# PIC16F1527 register map
Vendor: Microchip
Registers are 8-bit, read-write, no defined reset value unless marked. A register's access mark holds for its fields unless they carry their own. Addresses are absolute, and some are shared; only a register's first bit layout is shown; [hi:lo] are bit positions; {n}, {i} and the like mark numbered series; 'fields as' and 'values as' point back to an identical list.

## SFR
0x00 INDF0 — (power-on value xxxxxxxx)
0x01 INDF1 — (power-on value xxxxxxxx)
0x02 PCL reset 0x0
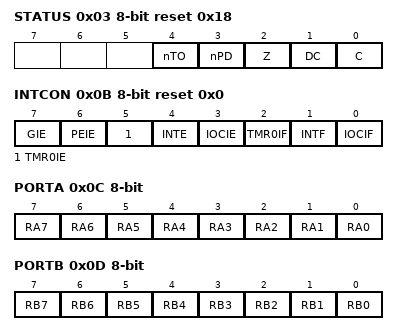
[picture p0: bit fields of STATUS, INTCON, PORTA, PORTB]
0x03 STATUS reset 0x18
  [4] nTO ro, [3] nPD ro, [2] Z, [1] DC, [0] C
0x04 FSR0L reset 0x0
0x05 FSR0H reset 0x0
0x06 FSR1L reset 0x0
0x07 FSR1H reset 0x0
0x08 BSR reset 0x0
  [4:0] BSR
0x09 WREG reset 0x0
  [7:0] WREG0
0x0A PCLATH reset 0x0
  [6:0] PCLATH
0x0B INTCON reset 0x0
  [7] GIE, [6] PEIE, [5] TMR0IE, [4] INTE, [3] IOCIE, [2] TMR0IF, [1] INTF, [0] IOCIF ro
0x0C PORTA — (power-on value xxxxxxxx)
  [n] RA{n} (n=0..7)
0x0D PORTB — (power-on value xxxxxxxx)
  [n] RB{n} (n=0..7)
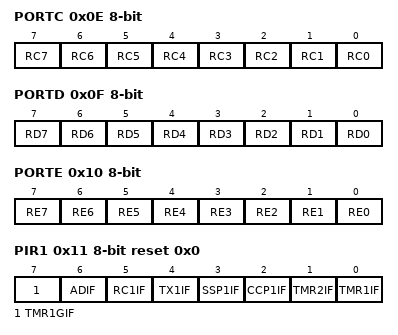
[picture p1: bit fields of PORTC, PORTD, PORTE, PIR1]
0x0E PORTC — (power-on value xxxxxxxx)
  [n] RC{n} (n=0..7)
0x0F PORTD — (power-on value xxxxxxxx)
  [n] RD{n} (n=0..7)
0x10 PORTE — (power-on value xxxxxxxx)
  [n] RE{n} (n=4..7), [3] RE3 ro, [2] RE2, [1] RE1, [0] RE0
0x11 PIR1 reset 0x0
  [7] TMR1GIF — Timer1 Gate Interrupt Flag bit
  [6] ADIF — A/D Converter Interrupt Flag bit
  [5] RC1IF ro — EUSART Receive Interrupt Flag bit
  [4] TX1IF ro — EUSART Transmit Interrupt Flag bit
  [3] SSP1IF — Master Synchronous Serial Port (MSSP) Interrupt Flag bit
  [2] CCP1IF — CCP1 Interrupt Flag bit
  [1] TMR2IF — TMR2 to PR2 Match Interrupt Flag bit
  [0] TMR1IF — TMR1 Overflow Interrupt Flag bit
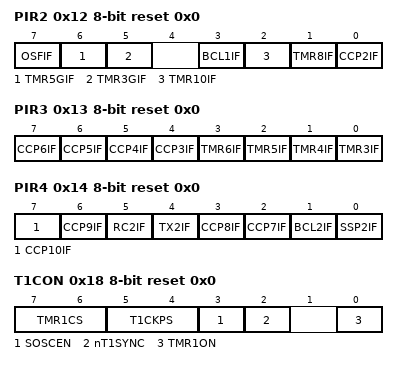
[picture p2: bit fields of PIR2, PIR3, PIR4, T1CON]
0x12 PIR2 reset 0x0
  [7] OSFIF, [6] TMR5GIF, [5] TMR3GIF, [3] BCL1IF, [2] TMR10IF, [1] TMR8IF, [0] CCP2IF
0x13 PIR3 reset 0x0
  [n+1] CCP{n}IF (n=3..6), [n-3] TMR{n}IF (n=3..6)
0x14 PIR4 reset 0x0
  [7] CCP10IF, [6] CCP9IF, [5] RC2IF, [4] TX2IF, [3] CCP8IF, [2] CCP7IF, [1] BCL2IF, [0] SSP2IF
0x15 TMR0 — (power-on value xxxxxxxx)
0x16 TMR1L — (power-on value xxxxxxxx)
0x17 TMR1H — (power-on value xxxxxxxx)
0x18 T1CON reset 0x0
  [7:6] TMR1CS, [5:4] T1CKPS, [3] SOSCEN, [2] nT1SYNC, [0] TMR1ON
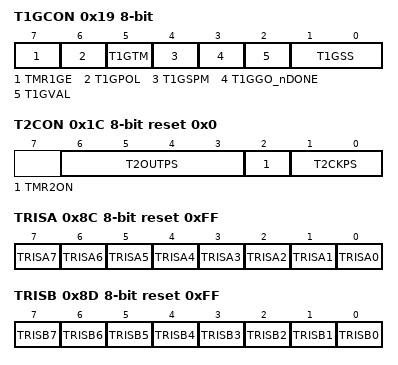
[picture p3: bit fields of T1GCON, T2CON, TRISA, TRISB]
0x19 T1GCON — (power-on value 00000x00)
  [7] TMR1GE, [6] T1GPOL, [5] T1GTM, [4] T1GSPM, [3] T1GGO_nDONE, [2] T1GVAL ro, [1:0] T1GSS
0x1A TMR2 reset 0x0
0x1B PR2 reset 0xFF
0x1C T2CON reset 0x0
  [6:3] T2OUTPS, [2] TMR2ON, [1:0] T2CKPS
0x8C TRISA reset 0xFF — PORTA Data Direction Control Register
  [n] TRISA{n} (n=0..7)
0x8D TRISB reset 0xFF — PORTB Data Direction Control Register
  [n] TRISB{n} (n=0..7)
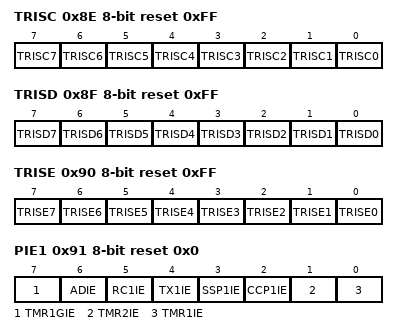
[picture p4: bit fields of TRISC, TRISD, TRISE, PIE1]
0x8E TRISC reset 0xFF — PORTC Data Direction Control Register
  [n] TRISC{n} (n=0..7)
0x8F TRISD reset 0xFF — PORTD Data Direction Control Register
  [n] TRISD{n} (n=0..7)
0x90 TRISE reset 0xFF — PORTE Data Direction Control Register
  [n] TRISE{n} (n=0..7)
0x91 PIE1 reset 0x0 — Peripheral Interrupt Enable Register 1
  [7] TMR1GIE — Timer1 Gate Interrupt Enable bit
  [6] ADIE — A/D Converter Interrupt Enable bit
  [5] RC1IE — EUSART Receive Interrupt Enable bit
  [4] TX1IE — EUSART Transmit Interrupt Enable bit
  [3] SSP1IE — Master Synchronous Serial Port (MSSP) Interrupt Enable bit
  [2] CCP1IE — CCP1 Interrupt Enable bit
  [1] TMR2IE — TMR2 to PR2 Match Interrupt Enable bit
  [0] TMR1IE — TMR1 Overflow Interrupt Enable bit
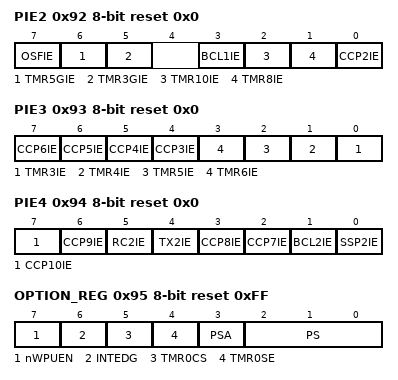
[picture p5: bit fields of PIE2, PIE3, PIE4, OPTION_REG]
0x92 PIE2 reset 0x0 — Peripheral Interrupt Enable Register 2
  [7] OSFIE — CCP2 Interrupt Enable bit
  [6] TMR5GIE
  [5] TMR3GIE
  [3] BCL1IE — MSSP Bus Collision Interrupt Interrupt Enable bit
  [2] TMR10IE
  [1] TMR8IE
  [0] CCP2IE — CCP2 Interrupt Enable bit
0x93 PIE3 reset 0x0 — Peripheral Interrupt Enable Register 3
  [n+1] CCP{n}IE (n=3..6), [n-3] TMR{n}IE (n=3..6)
0x94 PIE4 reset 0x0 — Peripheral Interrupt Enable Register 4
  [7] CCP10IE, [6] CCP9IE, [5] RC2IE, [4] TX2IE, [3] CCP8IE, [2] CCP7IE, [1] BCL2IE, [0] SSP2IE
0x95 OPTION_REG reset 0xFF — Option Register
  [7] nWPUEN — Weak Pull-up Enable bit
  [6] INTEDG — Interrupt Edge Select bit
  [5] TMR0CS — TMR0 Clock Source Select bit
  [4] TMR0SE — TMR0 Source Edge Select bit
  [3] PSA — Prescaler Active bit
  [2:0] PS
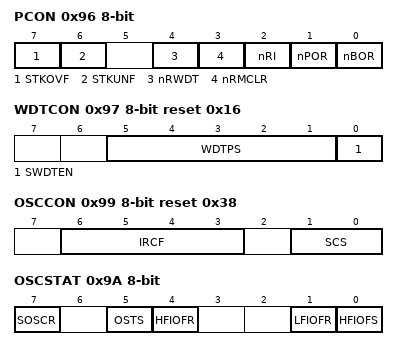
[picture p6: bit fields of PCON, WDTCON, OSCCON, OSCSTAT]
0x96 PCON — Power Control Register (power-on value 00-111qq)
  [7] STKOVF — Stack Overflow Flag bit
  [6] STKUNF — Stack Underflow Flag bit
  [4] nRWDT
  [3] nRMCLR — MCLR Reset Flag bit
  [2] nRI — RESET Instruction Flag bit
  [1] nPOR — Power-on Reset Status bit
  [0] nBOR — Brown-out Reset Status bit
0x97 WDTCON reset 0x16 — Watchdog Timer Control Register
  [5:1] WDTPS — Watchdog Timer Period Select bits
  [0] SWDTEN — Software Enable/Disable for Watch Dog Timer bit
0x99 OSCCON reset 0x38 — Oscillator Control Register
  [6:3] IRCF — Internal Oscillator Frequency Select bits
  [1:0] SCS — System clock select bit
0x9A OSCSTAT ro — Oscillator Status Register (power-on value 0-q0--00)
  [7] SOSCR — Secondary Oscillator Ready bit
  [5] OSTS — Oscillator Start-up Time-out Status bit
  [4] HFIOFR
  [1] LFIOFR — Low Freqency Internal Oscillator Ready bit
  [0] HFIOFS — Low Freqency Internal Oscillator Ready bit
0x9B ADRESL — A/D Result Register LSB (power-on value xxxxxxxx)
0x9C ADRESH — A/D Result Register MSB (power-on value xxxxxxxx)
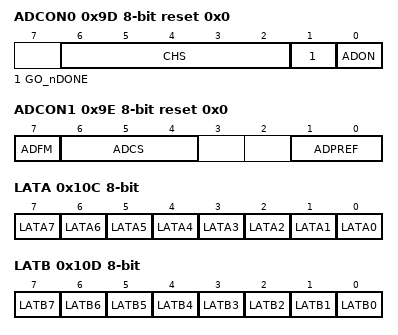
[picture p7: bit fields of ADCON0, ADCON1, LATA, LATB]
0x9D ADCON0 reset 0x0 — Analog-to-Digital Control Register 0
  [6:2] CHS — Analog Channel Select bits
  [1] GO_nDONE — A/D Conversion Status bit
  [0] ADON — A/D Module Enable bit
0x9E ADCON1 reset 0x0 — Analog-to-Digital Control Register 1
  [7] ADFM — A/D Result Format Select bit
  [6:4] ADCS — A/D Conversion Clock Select bits
  [1:0] ADPREF — A/D Positive Voltage Reference Configuration
0x10C LATA — (power-on value xxxxxxxx)
  [n] LATA{n} (n=0..7)
0x10D LATB — (power-on value xxxxxxxx)
  [n] LATB{n} (n=0..7)
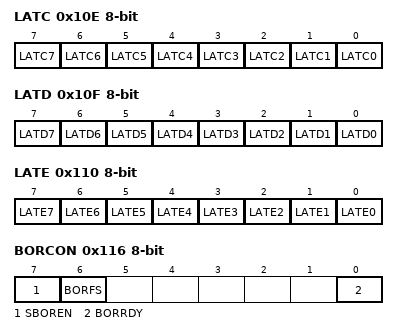
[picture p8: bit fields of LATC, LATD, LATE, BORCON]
0x10E LATC — (power-on value xxxxxxxx)
  [n] LATC{n} (n=0..7)
0x10F LATD — (power-on value xxxxxxxx)
  [n] LATD{n} (n=0..7)
0x110 LATE — (power-on value xxxxxxxx)
  [n] LATE{n} (n=0..7)
0x116 BORCON — Brown-out Reset Control Register (power-on value 10-----q)
  [7] SBOREN — Software Brown Out Reset Enable bit
  [6] BORFS
  [0] BORRDY ro — Brown-out Reset Circuit Ready Status bit
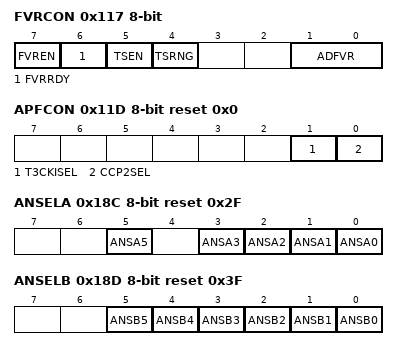
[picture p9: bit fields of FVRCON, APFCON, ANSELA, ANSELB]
0x117 FVRCON — Voltage Reference Control Register 0 (power-on value 0q00--00)
  [7] FVREN — Fixed Voltage Reference Enable
  [6] FVRRDY ro — Fixed Voltage Reference Ready Flag
  [5] TSEN — Temperature Sensor Enable
  [4] TSRNG — Temperature Sensor Range Select
  [1:0] ADFVR — A/D Converter Fixed Voltage Reference Selection
0x11D APFCON reset 0x0 — Alternate Pin Function Control Register
  [1] T3CKISEL
  [0] CCP2SEL — CCP2 Input/Output Pin Selection
0x18C ANSELA reset 0x2F
  [5] ANSA5, [n] ANSA{n} (n=0..3)
0x18D ANSELB reset 0x3F
  [n] ANSB{n} (n=0..5)
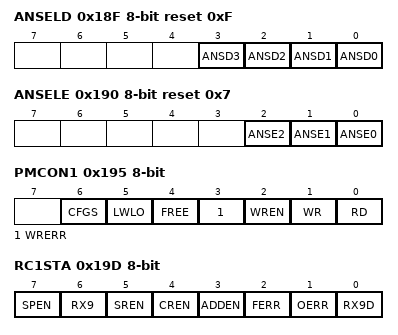
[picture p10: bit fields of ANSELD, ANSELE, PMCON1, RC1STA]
0x18F ANSELD reset 0xF
  [n] ANSD{n} (n=0..3)
0x190 ANSELE reset 0x7
  [2] ANSE2, [1] ANSE1, [0] ANSE0
0x191 PMADRL reset 0x0
0x192 PMADRH reset 0x80
  [6:0] PMADRH
0x193 PMDATL — (power-on value xxxxxxxx)
0x194 PMDATH — (power-on value --xxxxxx)
  [5:0] PMDATH
0x195 PMCON1 — (power-on value 1000x000)
  [6] CFGS — FLASH Program / Configuration Select bit
  [5] LWLO — Load Write Latches Only bit
  [4] FREE — Program FLASH Erase Enable bit
  [3] WRERR — Sequence Error Flag bit
  [2] WREN — Program/Erase Enable bit
  [1] WR — Write Control bit (can only be set)
  [0] RD — Read Control bit (can only be set)
0x196 PMCON2 wo
0x197 VREGCON reset 0x1
  [1] VREGPM
0x199 RC1REG ro reset 0x0
0x19A TX1REG reset 0x0
0x19B SP1BRGL reset 0x0
0x19C SP1BRGH reset 0x0
0x19D RC1STA — Receive Status and Control Register (power-on value 0000000x)
  [7] SPEN — Serial Port Enable bit
  [6] RX9 — 9-bit Receive Enable bit
  [5] SREN — Single Receive Enable bit
  [4] CREN — Continuous Receive Enable bit
  [3] ADDEN — Address Detect Enable bit
  [2] FERR ro — Framing Error bit
  [1] OERR ro — Overrun Error bit
  [0] RX9D ro — 9th bit of received data (can be parity bit)
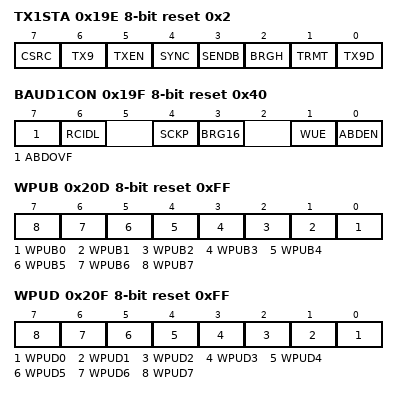
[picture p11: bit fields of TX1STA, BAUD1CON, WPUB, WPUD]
0x19E TX1STA reset 0x2 — Transmit Status and Control Register
  [7] CSRC — Clock Source Select bit
  [6] TX9 — 9-bit Transmit Enable bit
  [5] TXEN — Transmit Enable bit
  [4] SYNC — USART Mode Select bit
  [3] SENDB — Send BREAK character bit
  [2] BRGH — High Baud Rate Select bit
  [1] TRMT ro — Transmit Operation Idle Status bit
  [0] TX9D — 9th bit of transmit data; can be used as parity bit
0x19F BAUD1CON reset 0x40 — Baud Rate Control Register
  [7] ABDOVF — BRG Rollover Status bit
  [6] RCIDL ro — Receive Operation Idle Status bit
  [4] SCKP — Clock/Transmit Polarity Select bit
  [3] BRG16 — 16-bit Baud Rate Register enable bit
  [1] WUE — Wake-Up Enable bit
  [0] ABDEN — Auto-Baud Detect Enable bit
0x20D WPUB reset 0xFF
  [n] WPUB{n} (n=0..7)
0x20F WPUD reset 0xFF
  [n] WPUD{n} (n=0..7)
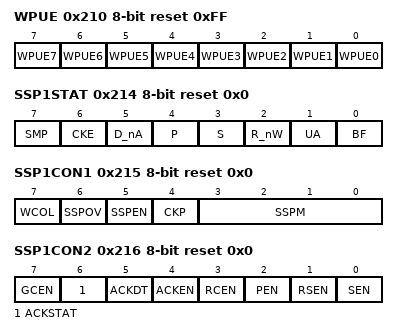
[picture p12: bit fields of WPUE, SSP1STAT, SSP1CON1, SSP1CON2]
0x210 WPUE reset 0xFF
  [n] WPUE{n} (n=0..7)
0x211 SSP1BUF — (power-on value xxxxxxxx)
  [7:0] SSPBUF
0x212 SSP1ADD reset 0x0
  [7:0] SSPADD
0x213 SSP1MSK reset 0xFF
  [7:0] SSPMSK
0x214 SSP1STAT reset 0x0
  [7] SMP, [6] CKE, [5] D_nA ro, [4] P ro, [3] S ro, [2] R_nW ro, [1] UA ro, [0] BF ro
0x215 SSP1CON1 reset 0x0
  [7] WCOL, [6] SSPOV, [5] SSPEN, [4] CKP, [3:0] SSPM
0x216 SSP1CON2 reset 0x0
  [7] GCEN, [6] ACKSTAT ro, [5] ACKDT, [4] ACKEN, [3] RCEN, [2] PEN, [1] RSEN, [0] SEN
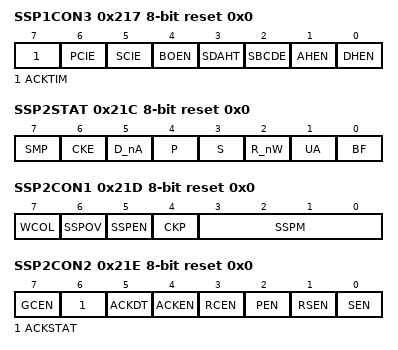
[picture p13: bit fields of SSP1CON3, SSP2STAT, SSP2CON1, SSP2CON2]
0x217 SSP1CON3 reset 0x0
  [7] ACKTIM ro, [6] PCIE, [5] SCIE, [4] BOEN, [3] SDAHT, [2] SBCDE, [1] AHEN, [0] DHEN
0x219 SSP2BUF — (power-on value xxxxxxxx)
  [7:0] SSPBUF
0x21A SSP2ADD reset 0x0
  [7:0] SSPADD
0x21B SSP2MSK reset 0xFF
  [7:0] SSPMSK
0x21C SSP2STAT reset 0x0
  fields as SSP1STAT
0x21D SSP2CON1 reset 0x0
  [7] WCOL, [6] SSPOV, [5] SSPEN, [4] CKP, [3:0] SSPM
0x21E SSP2CON2 reset 0x0
  fields as SSP1CON2
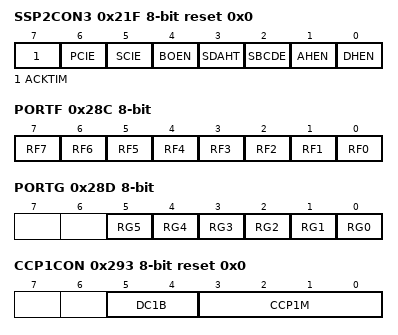
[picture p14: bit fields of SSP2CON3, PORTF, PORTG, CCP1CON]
0x21F SSP2CON3 reset 0x0
  fields as SSP1CON3
0x28C PORTF — (power-on value xxxxxxxx)
  [n] RF{n} (n=0..7)
0x28D PORTG — (power-on value --xxxxxx)
  [n] RG{n} (n=0..5)
0x291 CCPR1L — (power-on value xxxxxxxx)
0x292 CCPR1H — (power-on value xxxxxxxx)
0x293 CCP1CON reset 0x0
  [5:4] DC1B, [3:0] CCP1M
0x298 CCPR2L — (power-on value xxxxxxxx)
0x299 CCPR2H — (power-on value xxxxxxxx)
0x29A CCP2CON reset 0x0
  [5:4] DC2B, [3:0] CCP2M
0x29D CCPTMRS0 — (power-on value xxxxxxxx)
  [2n-1:2n-2] C{n}TSEL (n=1..4)
0x29E CCPTMRS1 — (power-on value xxxxxxxx)
  [2n-9:2n-10] C{n}TSEL (n=5..8)
0x29F CCPTMRS2 — (power-on value ----xxxx)
  [3:2] C10TSEL, [1:0] C9TSEL
0x30C TRISF reset 0xFF
  [n] TRISF{n} (n=0..7)
0x30D TRISG reset 0x3F
  [n] TRISG{n} (n=0..4)
0x311 CCPR3L — (power-on value xxxxxxxx)
0x312 CCPR3H — (power-on value xxxxxxxx)
0x313 CCP3CON reset 0x0
  [5:4] DC3B, [3:0] CCP3M
0x318 CCPR4L — (power-on value xxxxxxxx)
0x319 CCPR4H — (power-on value xxxxxxxx)
0x31A CCP4CON reset 0x0
  [5:4] DC4B, [3:0] CCP4M
0x31C CCPR5L — (power-on value xxxxxxxx)
0x31D CCPR5H — (power-on value xxxxxxxx)
0x31E CCP5CON reset 0x0
  [5:4] DC5B, [3:0] CCP5M
0x38C LATF — (power-on value xxxxxxxx)
  [n] LATF{n} (n=0..7)
0x38D LATG — (power-on value ---xxxxx)
  [n] LATG{n} (n=0..4)
0x394 IOCBP reset 0x0 — Interrupt-On-Change Positive Edge Register
  [n] IOCBP{n} (n=0..7)
0x395 IOCBN reset 0x0 — Interrupt-On-Change Negative Edge Register
  [n] IOCBN{n} (n=0..7)
0x396 IOCBF reset 0x0 — Interrupt-On-Change Flag Register
  [n] IOCBF{n} (n=0..7)
0x40C ANSELF reset 0xFF
  [n] ANSF{n} (n=0..7)
0x40D ANSELG reset 0x1E
  [n] ANSG{n} (n=1..4)
0x411 TMR3L — (power-on value xxxxxxxx)
0x412 TMR3H — (power-on value xxxxxxxx)
0x413 T3CON reset 0x0
  [7:6] TMR3CS, [5:4] T3CKPS, [3] SOSCEN, [2] nT3SYNC, [0] TMR3ON
0x414 T3GCON — (power-on value 00000x00)
  [7] TMR3GE, [6] T3GPOL, [5] T3GTM, [4] T3GSPM, [3] T3GGO_nDONE, [2] T3GVAL ro, [1:0] T3GSS
0x415 TMR4 reset 0x0
0x416 PR4 reset 0xFF
0x417 T4CON reset 0x0
  [6:3] T4OUTPS, [2] TMR4ON, [1:0] T4CKPS
0x418 TMR5L — (power-on value xxxxxxxx)
0x419 TMR5H — (power-on value xxxxxxxx)
0x41A T5CON reset 0x0
  [7:6] TMR5CS, [5:4] T5CKPS, [3] SOSCEN, [2] nT5SYNC, [0] TMR5ON
0x41B T5GCON — (power-on value 00000x00)
  [7] TMR5GE, [6] T5GPOL, [5] T5GTM, [4] T5GSPM, [3] T5GGO_nDONE, [2] T5GVAL ro, [1:0] T5GSS
0x41C TMR6 reset 0x0
0x41D PR6 reset 0xFF
0x41E T6CON reset 0x0
  [6:3] T6OUTPS, [2] TMR6ON, [1:0] T6CKPS
0x48D WPUG reset 0x20
  [5] WPUG5
0x491 RC2REG ro reset 0x0
0x492 TX2REG reset 0x0
0x493 SP2BRGL reset 0x0
0x494 SP2BRGH reset 0x0
0x495 RC2STA — Receive Status and Control Register (power-on value 0000000x)
  fields as RC1STA
0x496 TX2STA reset 0x2 — Transmit Status and Control Register
  fields as TX1STA
0x497 BAUD2CON reset 0x40 — Baud Rate Control Register
  fields as BAUD1CON
0x595 TMR8 reset 0x0
0x596 PR8 reset 0xFF
0x597 T8CON reset 0x0
  [6:3] T8OUTPS, [2] TMR8ON, [1:0] T8CKPS
0x59C TMR10 reset 0x0
0x59D PR10 reset 0xFF
0x59E T10CON reset 0x0
  [6:3] T10OUTPS, [2] TMR10ON, [1:0] T10CKPS
{0x5FF+3i} CCPR{i}L (i=6..10) — (power-on value xxxxxxxx)
{0x600+3i} CCPR{i}H (i=6..10) — (power-on value xxxxxxxx)
{0x601+3i} CCP{i}CON reset 0x0 (i=6..10)
  [5:4] DC{i}B, [3:0] CCP{i}M
0xFE4 STATUS_SHAD — (power-on value -----xxx)
  [2] Z_SHAD, [1] DC_SHAD, [0] C_SHAD
0xFE5 WREG_SHAD — (power-on value xxxxxxxx)
0xFE6 BSR_SHAD — (power-on value ---xxxxx)
  [4:0] BSR_SHAD
0xFE7 PCLATH_SHAD — (power-on value -xxxxxxx)
  [6:0] PCLATH_SHAD
0xFE8 FSR0L_SHAD — (power-on value xxxxxxxx)
0xFE9 FSR0H_SHAD — (power-on value xxxxxxxx)
0xFEA FSR1L_SHAD — (power-on value xxxxxxxx)
0xFEB FSR1H_SHAD — (power-on value xxxxxxxx)
0xFED STKPTR reset 0x1F — Current Stack pointer
  [4:0] STKPTR
0xFEE TOSL — Top of Stack Low byte (power-on value xxxxxxxx)
0xFEF TOSH — Top of Stack High byte (power-on value -xxxxxxx)
  [6:0] TOSH
